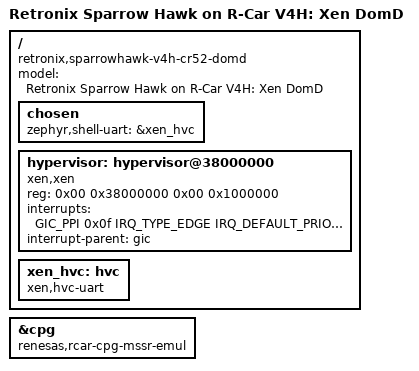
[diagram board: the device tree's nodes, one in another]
/*
 * Copyright (C) 2025 TOKITA Hiroshi
 *
 * SPDX-License-Identifier: Apache-2.0
 */

#include <mem.h>
#include <zephyr/dt-bindings/gpio/gpio.h>
#include <zephyr/dt-bindings/clock/r8a779g0_cpg_mssr.h>

/ {
        compatible = "retronix,sparrowhawk-v4h-cr52-domd";
        model = "Retronix Sparrow Hawk on R-Car V4H: Xen DomD";

	chosen {
		zephyr,shell-uart = &xen_hvc;
	};


	hypervisor: hypervisor@38000000 {
		compatible = "xen,xen";
		reg = <0x00 0x38000000 0x00 0x1000000>;
		interrupts = <GIC_PPI 0x0f IRQ_TYPE_EDGE IRQ_DEFAULT_PRIORITY>;
		interrupt-parent = <&gic>;
	};

	xen_hvc: hvc {
		compatible = "xen,hvc-uart";
		status = "okay";
	};
};

&cpg {
	compatible = "renesas,rcar-cpg-mssr-emul";
	#clock-cells = <2>;
};
